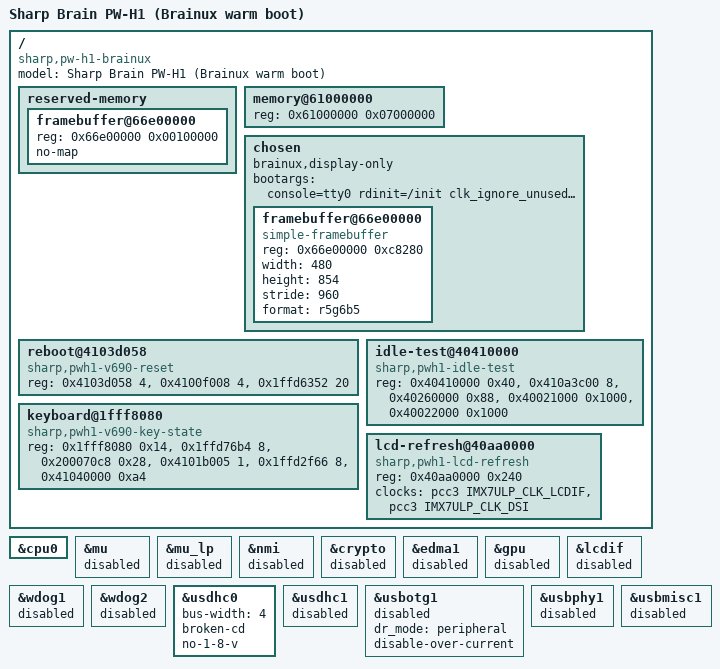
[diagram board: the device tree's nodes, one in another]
/dts-v1/;
#include "imx7ulp.dtsi"

/ {
    model = "Sharp Brain PW-H1 (Brainux warm boot)";
    compatible = "sharp,pw-h1-brainux", "fsl,imx7ulp";
    /delete-node/ reserved-memory;
    /delete-node/ heartbeat-rpmsg;
    /delete-node/ rtc-rpmsg;
    reserved-memory {
        #address-cells = <1>;
        #size-cells = <1>;
        ranges;
        framebuffer@66e00000 {
            reg = <0x66e00000 0x00100000>;
            no-map;
        };
    };
    memory@61000000 {
        device_type = "memory";
        reg = <0x61000000 0x07000000>;
    };
    chosen {
        // shortcut: isolate display until USB PHY reset no longer corrupts it.
        brainux,display-only;
        // shortcut: use polling until TPM wakeup is confirmed by wfi-test.
        bootargs = "console=tty0 rdinit=/init clk_ignore_unused loglevel=4 fbcon=rotate:1 nohlt";
        #address-cells = <1>;
        #size-cells = <1>;
        ranges;
        framebuffer@66e00000 {
            compatible = "simple-framebuffer";
            reg = <0x66e00000 0xc8280>;
            width = <480>;
            height = <854>;
            stride = <960>;
            format = "r5g6b5";
        };
    };
    reboot@4103d058 {
        compatible = "sharp,pwh1-v690-reset";
        reg = <0x4103d058 4>, <0x4100f008 4>, <0x1ffd6352 20>;
    };
    idle-test@40410000 {
        compatible = "sharp,pwh1-idle-test";
        reg = <0x40410000 0x40>, <0x410a3c00 8>, <0x40260000 0x88>,
              <0x40021000 0x1000>, <0x40022000 0x1000>;
    };
    keyboard@1fff8080 {
        compatible = "sharp,pwh1-v690-key-state";
        reg = <0x1fff8080 0x14>, <0x1ffd76b4 8>,
              <0x200070c8 0x28>, <0x4101b005 1>, <0x1ffd2f66 8>, <0x41040000 0xa4>;
    };
    lcd-refresh@40aa0000 {
        compatible = "sharp,pwh1-lcd-refresh";
        reg = <0x40aa0000 0x240>;
        clocks = <&pcc3 IMX7ULP_CLK_LCDIF>, <&pcc3 IMX7ULP_CLK_DSI>;
        clock-names = "lcdif", "dsi";
    };
};
&cpu0 { /delete-property/ operating-points-v2; };
&mu { status = "disabled"; };
&mu_lp { status = "disabled"; };
&nmi { status = "disabled"; };
&crypto { status = "disabled"; };
&edma1 { status = "disabled"; };
&gpu { status = "disabled"; };
&lcdif { status = "disabled"; };
&wdog1 { status = "disabled"; };
&wdog2 { status = "disabled"; };
// Keep the firmware's SD pin mux and power settings during initial bring-up.
&usdhc0 { status = "okay"; bus-width = <4>; broken-cd; no-1-8-v; };
&usdhc1 { status = "disabled"; };
&usbotg1 { status = "disabled"; dr_mode = "peripheral"; disable-over-current; };
&usbphy1 { status = "disabled"; };
&usbmisc1 { status = "disabled"; };
